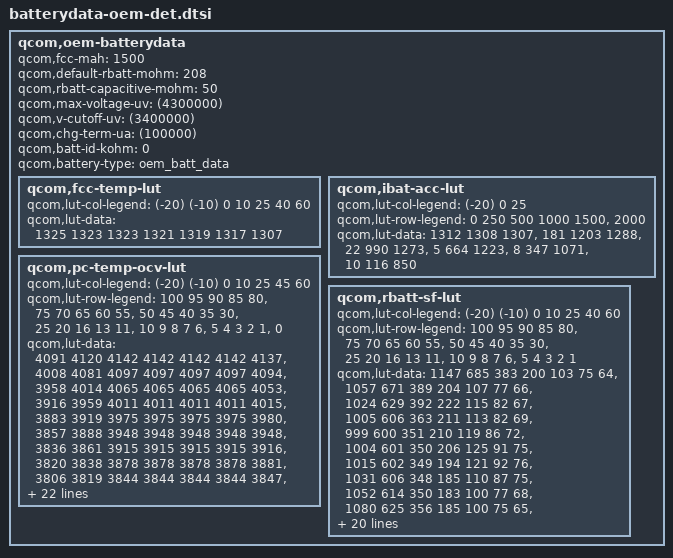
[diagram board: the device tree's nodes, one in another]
/* Copyright (c) 2013-2014, The Linux Foundation. All rights reserved.
 *
 * This program is free software; you can redistribute it and/or modify
 * it under the terms of the GNU General Public License version 2 and
 * only version 2 as published by the Free Software Foundation.
 *
 * This program is distributed in the hope that it will be useful,
 * but WITHOUT ANY WARRANTY; without even the implied warranty of
 * MERCHANTABILITY or FITNESS FOR A PARTICULAR PURPOSE.  See the
 * GNU General Public License for more details.
 */
/*
 * This software is contributed or developed by KYOCERA Corporation.
 * (C) 2016 KYOCERA Corporation
 * (C) 2017 KYOCERA Corporation
 */

qcom,oem-batterydata {
	qcom,fcc-mah = <1500>;
	qcom,default-rbatt-mohm = <208>;
	qcom,rbatt-capacitive-mohm = <50>;
	qcom,max-voltage-uv = <(4300000)>;
	qcom,v-cutoff-uv = <(3400000)>;
	qcom,chg-term-ua = <(100000)>;
	qcom,batt-id-kohm = <0>;
	qcom,battery-type = "oem_batt_data";

	qcom,fcc-temp-lut {
		qcom,lut-col-legend = <(-20) (-10) 0 10 25 40 60>;
		qcom,lut-data = <1325 1323 1323 1321 1319 1317 1307>;
	};

	qcom,ibat-acc-lut {
		qcom,lut-col-legend = <(-20) 0 25>;
		qcom,lut-row-legend = <0 250 500 1000 1500>,
				<2000>;
		qcom,lut-data = <1312 1308 1307>,
						< 181 1203 1288>,
						<  22  990 1273>,
						<   5  664 1223>,
						<   8  347 1071>,
						<  10  116  850>;
	};

	qcom,pc-temp-ocv-lut {
		qcom,lut-col-legend = <(-20) (-10) 0 10 25 45 60>;
		qcom,lut-row-legend = <100 95 90 85 80>,
				<75 70 65 60 55>,
				<50 45 40 35 30>,
				<25 20 16 13 11>,
				<10 9 8 7 6>,
				<5 4 3 2 1>,
				<0>;
		qcom,lut-data = <4091 4120 4142 4142 4142 4142 4137>,
						<4008 4081 4097 4097 4097 4097 4094>,
						<3958 4014 4065 4065 4065 4065 4053>,
						<3916 3959 4011 4011 4011 4011 4015>,
						<3883 3919 3975 3975 3975 3975 3980>,
						<3857 3888 3948 3948 3948 3948 3948>,
						<3836 3861 3915 3915 3915 3915 3916>,
						<3820 3838 3878 3878 3878 3878 3881>,
						<3806 3819 3844 3844 3844 3844 3847>,
						<3792 3803 3822 3822 3822 3822 3824>,
						<3779 3788 3804 3804 3804 3804 3806>,
						<3765 3774 3791 3791 3791 3791 3792>,
						<3753 3761 3781 3781 3781 3781 3779>,
						<3740 3748 3773 3773 3773 3773 3765>,
						<3729 3738 3765 3765 3765 3765 3748>,
						<3716 3729 3752 3752 3752 3752 3729>,
						<3700 3720 3732 3732 3732 3732 3709>,
						<3686 3713 3708 3708 3708 3708 3687>,
						<3671 3704 3692 3692 3692 3692 3672>,
						<3658 3697 3688 3688 3688 3688 3669>,
						<3651 3692 3687 3687 3687 3687 3668>,
						<3644 3685 3686 3686 3686 3686 3667>,
						<3634 3679 3685 3685 3685 3685 3667>,
						<3624 3671 3683 3683 3683 3683 3665>,
						<3612 3661 3680 3680 3680 3680 3660>,
						<3598 3647 3672 3672 3672 3672 3647>,
						<3578 3628 3652 3652 3652 3652 3620>,
						<3554 3603 3614 3614 3614 3614 3579>,
						<3523 3566 3564 3564 3564 3564 3528>,
						<3478 3514 3500 3500 3500 3500 3462>,
						<3400 3400 3400 3400 3400 3400 3400>;
	};

	qcom,rbatt-sf-lut {
		qcom,lut-col-legend = <(-20) (-10) 0 10 25 40 60>;
		qcom,lut-row-legend = <100 95 90 85 80>,
				<75 70 65 60 55>,
				<50 45 40 35 30>,
				<25 20 16 13 11>,
				<10 9 8 7 6>,
				<5 4 3 2 1>;
		qcom,lut-data = <1147  685 383 200 103 75 64>,
						<1057  671 389 204 107 77 66>,
						<1024  629 392 222 115 82 67>,
						<1005  606 363 211 113 82 69>,
						< 999  600 351 210 119 86 72>,
						<1004  601 350 206 125 91 75>,
						<1015  602 349 194 121 92 76>,
						<1031  606 348 185 110 87 75>,
						<1052  614 350 183 100 77 68>,
						<1080  625 356 185 100 75 65>,
						<1110  640 369 188 101 77 67>,
						<1143  660 385 195 103 79 70>,
						<1212  686 404 206 107 81 73>,
						<1314  719 425 220 111 82 72>,
						<1462  758 445 235 114 82 69>,
						<1677  806 468 251 116 81 67>,
						<1970  862 501 262 118 80 67>,
						<2279  912 544 269 117 79 67>,
						<2564  951 587 285 117 78 66>,
						<2768  967 615 301 122 82 68>,
						<2804  959 615 307 125 83 69>,
						<2823  951 613 312 128 85 71>,
						<2871  943 609 317 131 87 71>,
						<3033  944 610 324 133 88 72>,
						<3351  965 625 335 137 89 72>,
						<3731 1002 647 348 139 88 70>,
						<4201 1063 670 357 138 85 68>,
						<4827 1166 699 367 138 85 69>,
						<5663 1345 737 392 145 89 73>,
						<6935 1647 791 430 156 95 78>;
	};
};
